# mc200 register map
Registers are 32-bit, access not given, no defined reset value unless marked. A register's access mark holds for its fields unless they carry their own. Addresses are absolute; registers are grouped by the start of their names; [hi:lo] are bit positions; {n}, {i} and the like mark numbered series.

## GPT2
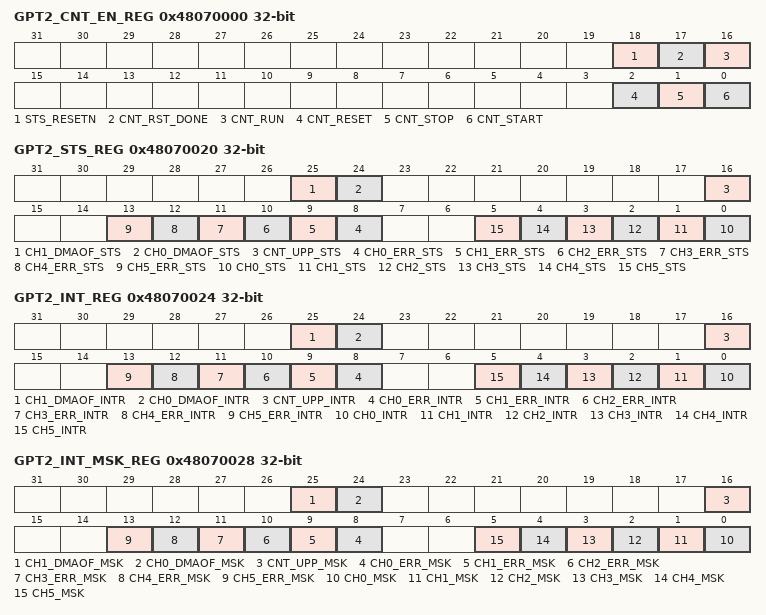
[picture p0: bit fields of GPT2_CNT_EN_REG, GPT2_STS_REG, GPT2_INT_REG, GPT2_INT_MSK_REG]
0x48070000 GPT2_CNT_EN_REG
  [18] STS_RESETN, [17] CNT_RST_DONE, [16] CNT_RUN, [2] CNT_RESET, [1] CNT_STOP, [0] CNT_START
0x48070020 GPT2_STS_REG
  [25] CH1_DMAOF_STS, [24] CH0_DMAOF_STS, [16] CNT_UPP_STS, [n+8] CH{n}_ERR_STS (n=0..5), [n] CH{n}_STS (n=0..5)
0x48070024 GPT2_INT_REG
  [25] CH1_DMAOF_INTR, [24] CH0_DMAOF_INTR, [16] CNT_UPP_INTR, [n+8] CH{n}_ERR_INTR (n=0..5), [n] CH{n}_INTR (n=0..5)
0x48070028 GPT2_INT_MSK_REG
  [25] CH1_DMAOF_MSK, [24] CH0_DMAOF_MSK, [16] CNT_UPP_MSK, [n+8] CH{n}_ERR_MSK (n=0..5), [n] CH{n}_MSK (n=0..5)
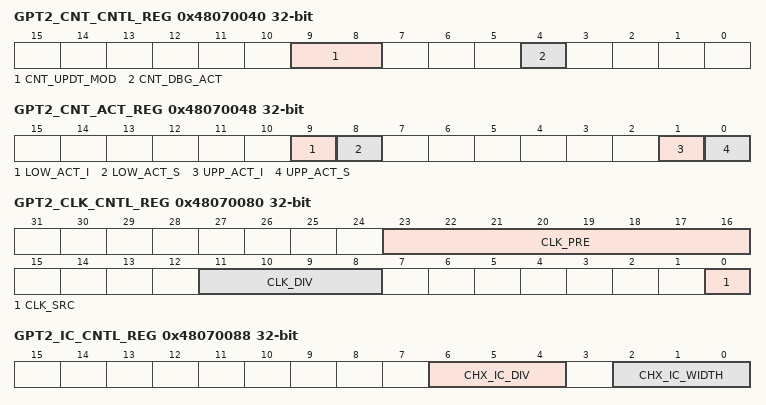
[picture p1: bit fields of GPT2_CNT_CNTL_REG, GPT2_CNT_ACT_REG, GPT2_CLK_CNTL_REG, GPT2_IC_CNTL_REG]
0x48070040 GPT2_CNT_CNTL_REG
  [9:8] CNT_UPDT_MOD, [4] CNT_DBG_ACT
0x48070048 GPT2_CNT_ACT_REG
  [9] LOW_ACT_I, [8] LOW_ACT_S, [1] UPP_ACT_I, [0] UPP_ACT_S
0x48070050 GPT2_CNT_VAL_REG
  [31:0] CNT_VAL
0x48070060 GPT2_CNT_UPP_VAL_REG
  [31:0] UPP_VAL
0x48070080 GPT2_CLK_CNTL_REG
  [23:16] CLK_PRE, [11:8] CLK_DIV, [0] CLK_SRC
0x48070088 GPT2_IC_CNTL_REG
  [6:4] CHX_IC_DIV, [2:0] CHX_IC_WIDTH
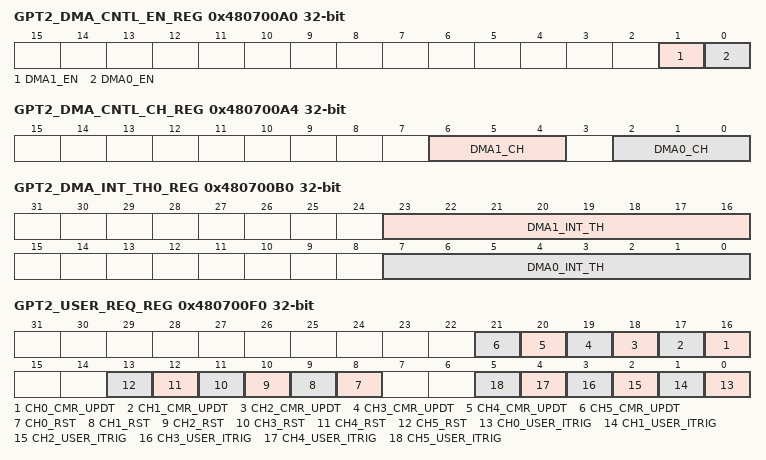
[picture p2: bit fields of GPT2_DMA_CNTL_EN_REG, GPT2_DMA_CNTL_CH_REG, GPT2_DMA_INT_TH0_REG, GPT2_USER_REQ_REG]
0x480700A0 GPT2_DMA_CNTL_EN_REG
  [1] DMA1_EN, [0] DMA0_EN
0x480700A4 GPT2_DMA_CNTL_CH_REG
  [6:4] DMA1_CH, [2:0] DMA0_CH
0x480700B0 GPT2_DMA_INT_TH0_REG
  [23:16] DMA1_INT_TH, [7:0] DMA0_INT_TH
0x480700D0 GPT2_ADCT_REG
  [2:0] ADCT_CHSEL
0x480700D8 GPT2_ADCT_DLY_REG
  [31:0] ADCT_DLY
0x480700F0 GPT2_USER_REQ_REG
  [n+16] CH{n}_CMR_UPDT (n=0..5), [n+8] CH{n}_RST (n=0..5), [n] CH{n}_USER_ITRIG (n=0..5)
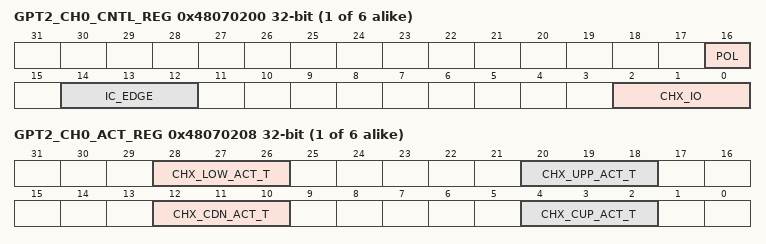
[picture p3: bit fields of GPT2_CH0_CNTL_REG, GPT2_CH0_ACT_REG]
{0x48070200+0x40*i} GPT2_CH{i}_CNTL_REG (i=0..5)
  [16] POL, [14:12] IC_EDGE, [2:0] CHX_IO
{0x48070208+0x40*i} GPT2_CH{i}_ACT_REG (i=0..5)
  [28:26] CHX_LOW_ACT_T, [20:18] CHX_UPP_ACT_T, [12:10] CHX_CDN_ACT_T, [4:2] CHX_CUP_ACT_T
{0x48070210+0x40*i} GPT2_CH{i}_CMR0_REG (i=0..5)
  [29:0] CMR0
{0x48070214+0x40*i} GPT2_CH{i}_STS_REG (i=0..5)
  [0] OUT_ST
{0x48070220+0x40*i} GPT2_CH{i}_CMR1_REG (i=0..5)
  [29:0] CMR1

## GPT3
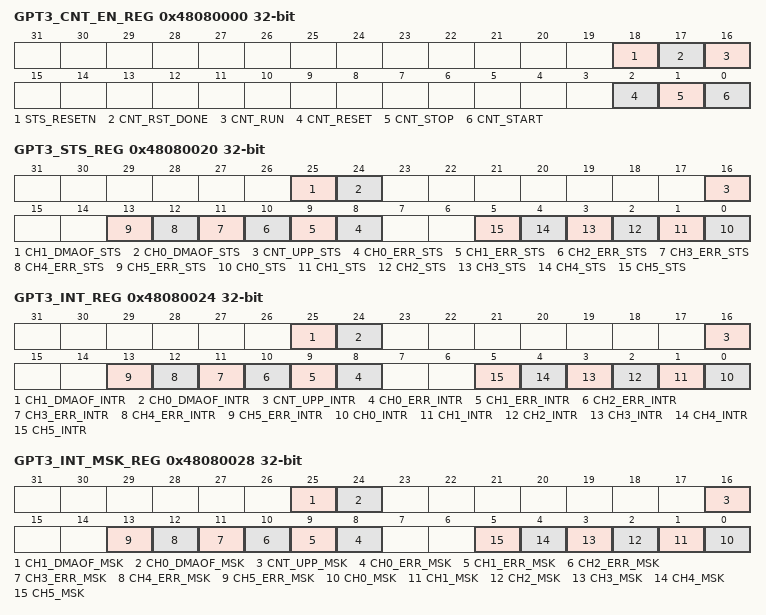
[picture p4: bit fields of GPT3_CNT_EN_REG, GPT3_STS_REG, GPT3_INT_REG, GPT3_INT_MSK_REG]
0x48080000 GPT3_CNT_EN_REG
  [18] STS_RESETN, [17] CNT_RST_DONE, [16] CNT_RUN, [2] CNT_RESET, [1] CNT_STOP, [0] CNT_START
0x48080020 GPT3_STS_REG
  [25] CH1_DMAOF_STS, [24] CH0_DMAOF_STS, [16] CNT_UPP_STS, [n+8] CH{n}_ERR_STS (n=0..5), [n] CH{n}_STS (n=0..5)
0x48080024 GPT3_INT_REG
  [25] CH1_DMAOF_INTR, [24] CH0_DMAOF_INTR, [16] CNT_UPP_INTR, [n+8] CH{n}_ERR_INTR (n=0..5), [n] CH{n}_INTR (n=0..5)
0x48080028 GPT3_INT_MSK_REG
  [25] CH1_DMAOF_MSK, [24] CH0_DMAOF_MSK, [16] CNT_UPP_MSK, [n+8] CH{n}_ERR_MSK (n=0..5), [n] CH{n}_MSK (n=0..5)
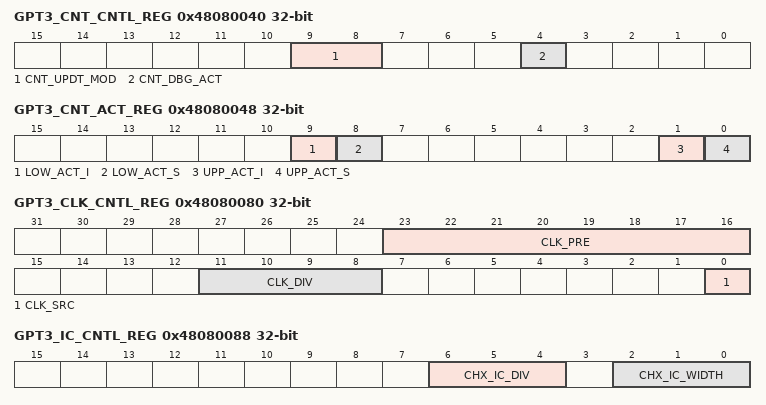
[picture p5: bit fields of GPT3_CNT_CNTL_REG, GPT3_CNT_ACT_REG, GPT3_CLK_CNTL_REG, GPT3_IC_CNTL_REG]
0x48080040 GPT3_CNT_CNTL_REG
  [9:8] CNT_UPDT_MOD, [4] CNT_DBG_ACT
0x48080048 GPT3_CNT_ACT_REG
  [9] LOW_ACT_I, [8] LOW_ACT_S, [1] UPP_ACT_I, [0] UPP_ACT_S
0x48080050 GPT3_CNT_VAL_REG
  [31:0] CNT_VAL
0x48080060 GPT3_CNT_UPP_VAL_REG
  [31:0] UPP_VAL
0x48080080 GPT3_CLK_CNTL_REG
  [23:16] CLK_PRE, [11:8] CLK_DIV, [0] CLK_SRC
0x48080088 GPT3_IC_CNTL_REG
  [6:4] CHX_IC_DIV, [2:0] CHX_IC_WIDTH
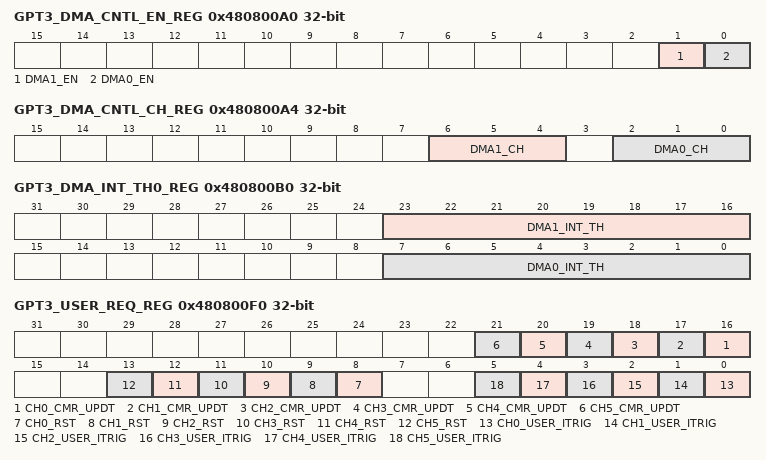
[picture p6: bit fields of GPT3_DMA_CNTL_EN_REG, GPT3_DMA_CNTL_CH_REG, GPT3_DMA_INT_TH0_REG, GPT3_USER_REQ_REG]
0x480800A0 GPT3_DMA_CNTL_EN_REG
  [1] DMA1_EN, [0] DMA0_EN
0x480800A4 GPT3_DMA_CNTL_CH_REG
  [6:4] DMA1_CH, [2:0] DMA0_CH
0x480800B0 GPT3_DMA_INT_TH0_REG
  [23:16] DMA1_INT_TH, [7:0] DMA0_INT_TH
0x480800D0 GPT3_ADCT_REG
  [2:0] ADCT_CHSEL
0x480800D8 GPT3_ADCT_DLY_REG
  [31:0] ADCT_DLY
0x480800F0 GPT3_USER_REQ_REG
  [n+16] CH{n}_CMR_UPDT (n=0..5), [n+8] CH{n}_RST (n=0..5), [n] CH{n}_USER_ITRIG (n=0..5)
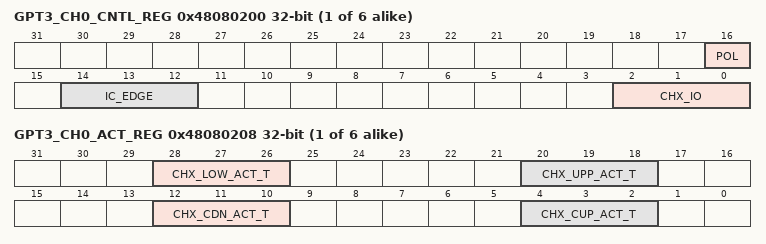
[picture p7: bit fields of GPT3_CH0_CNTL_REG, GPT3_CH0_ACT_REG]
{0x48080200+0x40*i} GPT3_CH{i}_CNTL_REG (i=0..5)
  [16] POL, [14:12] IC_EDGE, [2:0] CHX_IO
{0x48080208+0x40*i} GPT3_CH{i}_ACT_REG (i=0..5)
  [28:26] CHX_LOW_ACT_T, [20:18] CHX_UPP_ACT_T, [12:10] CHX_CDN_ACT_T, [4:2] CHX_CUP_ACT_T
{0x48080210+0x40*i} GPT3_CH{i}_CMR0_REG (i=0..5)
  [29:0] CMR0
{0x48080214+0x40*i} GPT3_CH{i}_STS_REG (i=0..5)
  [0] OUT_ST
{0x48080220+0x40*i} GPT3_CH{i}_CMR1_REG (i=0..5)
  [29:0] CMR1

## RTC
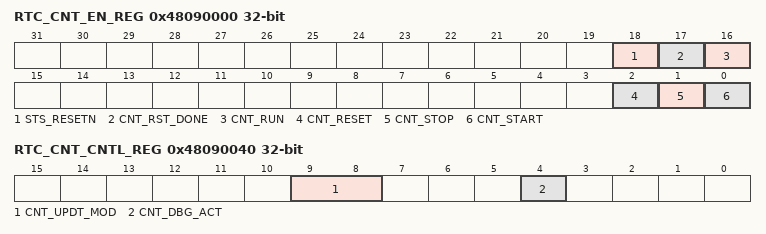
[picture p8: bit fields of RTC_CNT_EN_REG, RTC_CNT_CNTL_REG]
0x48090000 RTC_CNT_EN_REG
  [18] STS_RESETN, [17] CNT_RST_DONE, [16] CNT_RUN, [2] CNT_RESET, [1] CNT_STOP, [0] CNT_START
0x48090020 RTC_INT_RAW_REG
  [16] CNT_UPP_INT
0x48090024 RTC_INT_REG
  [16] CNT_UPP_INTR
0x48090028 RTC_INT_MSK_REG
  [16] CNT_UPP_MSK
0x48090040 RTC_CNT_CNTL_REG
  [9:8] CNT_UPDT_MOD, [4] CNT_DBG_ACT
0x48090050 RTC_CNT_VAL_REG
  [31:0] CNT_VAL
0x48090060 RTC_CNT_UPP_VAL_REG
  [31:0] UPP_VAL

## SYS
0x480B0000 SYS_CTRL_REV_ID
  [31:0] REV_ID
0x480B0004 SYS_CTRL_MEM
  [7:0] CFG
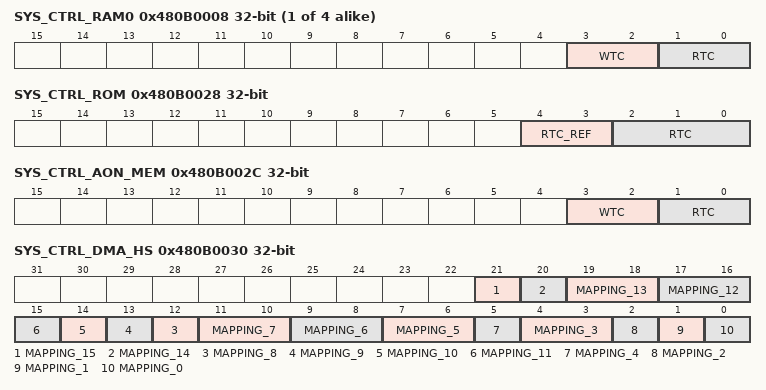
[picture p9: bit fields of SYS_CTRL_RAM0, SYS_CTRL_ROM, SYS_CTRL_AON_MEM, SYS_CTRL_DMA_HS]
{0x480B0008+4i} SYS_CTRL_RAM{i} (i=0..3)
  [3:2] WTC, [1:0] RTC
{0x480B0008+4i} SYS_CTRL_RESERVED{i} (i=4..7)
0x480B0028 SYS_CTRL_ROM
  [4:3] RTC_REF, [2:0] RTC
0x480B002C SYS_CTRL_AON_MEM
  [3:2] WTC, [1:0] RTC
0x480B0030 SYS_CTRL_DMA_HS
  [21] MAPPING_15, [20] MAPPING_14, [19:18] MAPPING_13, [17:16] MAPPING_12, [n+4] MAPPING_{n} (n=8..11), [11:10] MAPPING_7, [9:8] MAPPING_6, [7:6] MAPPING_5, [5] MAPPING_4, [4:3] MAPPING_3, [2] MAPPING_2, [1] MAPPING_1, [0] MAPPING_0
0x480B0034 SYS_CTRL_GPT_IN
  [0] SEL
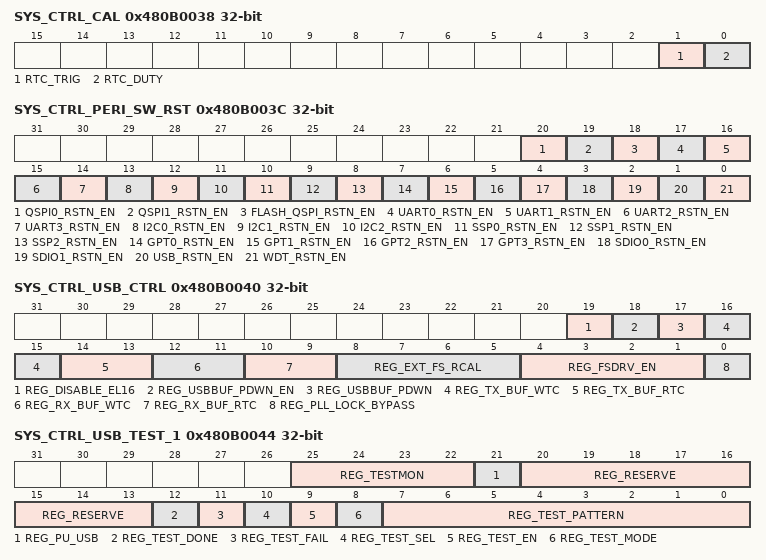
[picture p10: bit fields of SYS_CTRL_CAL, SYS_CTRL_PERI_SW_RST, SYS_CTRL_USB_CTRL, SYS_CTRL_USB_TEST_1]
0x480B0038 SYS_CTRL_CAL
  [1] RTC_TRIG, [0] RTC_DUTY
0x480B003C SYS_CTRL_PERI_SW_RST
  [20] QSPI0_RSTN_EN, [19] QSPI1_RSTN_EN, [18] FLASH_QSPI_RSTN_EN, [17-n] UART{n}_RSTN_EN (n=0..3), [13] I2C0_RSTN_EN, [12] I2C1_RSTN_EN, [11] I2C2_RSTN_EN, [10] SSP0_RSTN_EN, [9] SSP1_RSTN_EN, [8] SSP2_RSTN_EN, [7-n] GPT{n}_RSTN_EN (n=0..3), [3] SDIO0_RSTN_EN, [2] SDIO1_RSTN_EN, [1] USB_RSTN_EN, [0] WDT_RSTN_EN
0x480B0040 SYS_CTRL_USB_CTRL
  [19] REG_DISABLE_EL16, [18] REG_USBBUF_PDWN_EN, [17] REG_USBBUF_PDWN, [16:15] REG_TX_BUF_WTC, [14:13] REG_TX_BUF_RTC, [12:11] REG_RX_BUF_WTC, [10:9] REG_RX_BUF_RTC, [8:5] REG_EXT_FS_RCAL, [4:1] REG_FSDRV_EN, [0] REG_PLL_LOCK_BYPASS
0x480B0044 SYS_CTRL_USB_TEST_1
  [25:22] REG_TESTMON, [21] REG_PU_USB, [20:13] REG_RESERVE, [12] REG_TEST_DONE, [11] REG_TEST_FAIL, [10] REG_TEST_SEL, [9] REG_TEST_EN, [8] REG_TEST_MODE, [7:0] REG_TEST_PATTERN
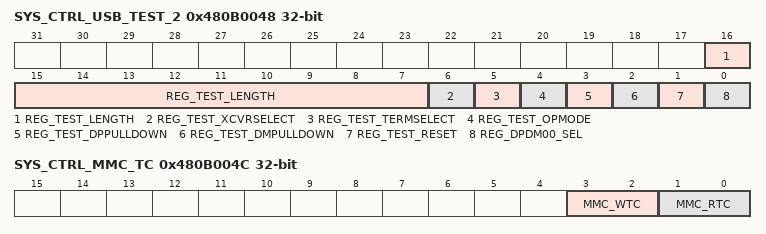
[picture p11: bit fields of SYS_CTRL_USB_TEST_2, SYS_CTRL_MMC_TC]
0x480B0048 SYS_CTRL_USB_TEST_2
  [16:7] REG_TEST_LENGTH, [6] REG_TEST_XCVRSELECT, [5] REG_TEST_TERMSELECT, [4] REG_TEST_OPMODE, [3] REG_TEST_DPPULLDOWN, [2] REG_TEST_DMPULLDOWN, [1] REG_TEST_RESET, [0] REG_DPDM00_SEL
0x480B004C SYS_CTRL_MMC_TC
  [3:2] MMC_WTC, [1:0] MMC_RTC
